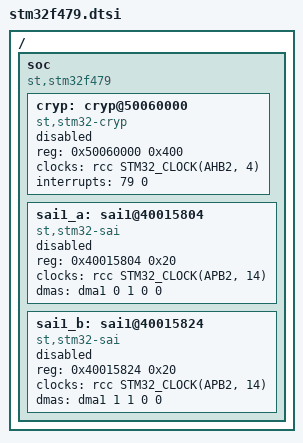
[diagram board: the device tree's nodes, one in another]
/*
 * Copyright (C) 2025 Christopher Cichiwskyj
 * Copyright (c) 2025 Mario Paja <mariopaja@hotmail.com>
 *
 * SPDX-License-Identifier: Apache-2.0
 */

#include <st/f4/stm32f469.dtsi>

/ {
	soc {
		compatible = "st,stm32f479", "st,stm32f4", "simple-bus";

		cryp: cryp@50060000 {
			compatible = "st,stm32-cryp";
			reg = <0x50060000 0x400>;
			clocks = <&rcc STM32_CLOCK(AHB2, 4)>;
			interrupts = <79 0>;
			status = "disabled";
		};

		sai1_a: sai1@40015804 {
			compatible = "st,stm32-sai";
			#address-cells = <1>;
			#size-cells = <0>;
			reg = <0x40015804 0x20>;
			clocks = <&rcc STM32_CLOCK(APB2, 14)>;
			dmas = <&dma1 0 1 0 0>;
			status = "disabled";
		};

		sai1_b: sai1@40015824 {
			compatible = "st,stm32-sai";
			#address-cells = <1>;
			#size-cells = <0>;
			reg = <0x40015824 0x20>;
			clocks = <&rcc STM32_CLOCK(APB2, 14)>;
			dmas = <&dma1 1 1 0 0>;
			status = "disabled";
		};
	};
};
